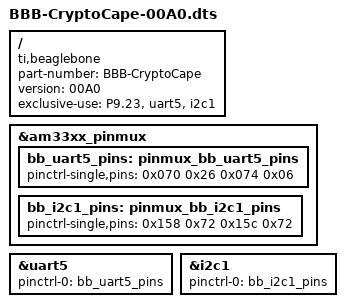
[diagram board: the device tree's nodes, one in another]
/dts-v1/;
/plugin/;

/ {
    compatible = "ti,beaglebone", "ti,beaglebone-black";

    part-number = "BBB-CryptoCape";
    version = "00A0";
    exclusive-use =
        "P9.23",
        "uart5",
        "i2c1";
    fragment@0 {
        target = <&am33xx_pinmux>;
        __overlay__{
            bb_uart5_pins: pinmux_bb_uart5_pins {
                pinctrl-single,pins = <
                0x070 0x26  /* P9_11 = GPIO0_30 = GPMC_WAIT0 , MODE6 */
                0x074 0x06  /* P9_13 = GPIO0_31 = GPMC_WPN, MODE6 */
                >;
           };
        };
    };
    fragment@1 {
        target = <&uart5>;
        __overlay__{
            status = "okay";
            pinctrl-names = "default";
            pinctrl-0 = <&bb_uart5_pins>;
        };
    };
    fragment@2 {
        target = <&am33xx_pinmux>;
        __overlay__{
            bb_i2c1_pins: pinmux_bb_i2c1_pins {
                pinctrl-single,pins = <
               0x158 0x72
               0x15c 0x72
                >;
           };
        };
    };
    fragment@3 {
        target = <&i2c1>;
        __overlay__{
            status = "okay";
            pinctrl-names = "default";
            pinctrl-0 = <&bb_i2c1_pins>;
        };
    };
};
